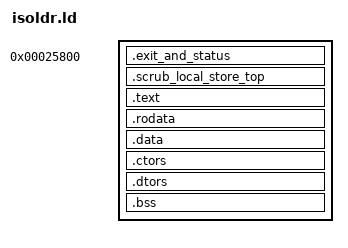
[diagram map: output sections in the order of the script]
ENTRY(_start)

SECTIONS
{
  . = 0x25800;

  .exit_and_status :
  {
    */isoldr/src/exit_stop.o(.text.exit_stop)
    */isoldr/src/exit_stop.o(.data.exit_status)
  }

  .scrub_local_store_top :
  {
    */isoldr/src/scrub.o(.text.scrub)
  }

  .text ALIGN(0x10) :
  {
    */isoldr/src/crt0.o(.text)
    */isoldr/src/g_loader.o(.text._Z41__static_initialization_and_destruction_0ii)
    */isoldr/src/g_loader.o(.text._GLOBAL__I_g_loader)
    */isoldr/src/main.o(.text.main)
    */isoldr/src/loader.o(.text._ZN6loader13apply_qa_flagEv)
    */isoldr/src/loader.o(.text._ZN6loader14check_revisionEv)
    */isoldr/src/loader.o(.text._ZN6loader13select_keysetEt)
    *(.text._ZN9encryptorD0Ev)
    *(.text._ZN9encryptorD1Ev)
    *(.text._ZN9encryptorD2Ev)
    */isoldr/src/encryptor_aes256_cbc.o(.text._ZN20aes256_cbc_encryptorD0Ev)
    *(.text._ZN20aes256_cbc_encryptorD1Ev)
    */isoldr/src/encryptor_aes256_cbc.o(.text._Z41__static_initialization_and_destruction_0ii)
    */isoldr/src/encryptor_aes256_cbc.o(.text._GLOBAL__D_g_aes256_cbc_encryptor)
    */isoldr/src/encryptor_aes256_cbc.o(.text._GLOBAL__I_g_aes256_cbc_encryptor)
    */isoldr/src/loader.o(.text._ZN6loader11export_keysEP7spu_regS1_S1_)
    */isoldr/src/loader.o(.text._ZN6loader12read_requestEv)
    */isoldr/src/loader.o(.text._ZN6loader10takes_keysEv)
    */isoldr/src/loader.o(.text._ZN6loader10load_stateEv)
    */isoldr/src/loader.o(.text._ZN6loaderC1Ev)
    */isoldr/src/loader.o(.text._ZN6loaderC2Ev)
    */isoldr/src/loader.o(.text._ZN6loader13check_qa_flagEv)
    */isoldr/src/loader.o(.text._ZN6loader11open_paramsEv)
    */isoldr/src/loader.o(.text._ZN6loader12export_stateEP7spu_regS1_S1_S1_S1_S1_S1_S1_S1_S1_S1_S1_S1_S1_S1_S1_)
    *(.text._ZN12local_bufferD1Ev)
    *(.text._ZN17tagged_dma_bufferD1Ev)
    */isoldr/src/loader.o(.text._ZN6loader11load_headerEv)
    */isoldr/src/loader.o(.text._ZN6loader17check_revoke_listEv)
    */isoldr/src/loader.o(.text._ZN6loader13load_segmentsEPPFvvE)
    */isoldr/src/loader.o(.text._ZN6loader4loadEPPFvvE)
    */isoldr/src/loader.o(.text._ZN6loader3runEPyS0_S0_S0_P7spu_regS2_S2_S2_S2_S2_S2_S2_S2_S2_S2_S2_S2_S2_S2_S2_PPFvvES0_)
    *(.text._ZN6cipher6vslot6EPKv)
    *(.text._ZN6cipher6vslot7EPv)
    */isoldr/src/hmac_digest.o(.text._ZN11hmac_digestC1Ev)
    */isoldr/src/hmac_digest.o(.text._ZN11hmac_digestC2Ev)
    */lv2ldr/src/hash_reader.o(.text._Z12bytes_differPKhS0_i)
    */isoldr/src/qa_flag.o(.text._ZN14qa_flag_reader4initEv)
    *(.text._ZN6cipherD0Ev)
    *(.text._ZN6cipherD1Ev)
    *(.text._ZN6cipherD2Ev)
    */isoldr/src/cipher_aes256_cbc.o(.text._ZN17aes256_cbc_cipherD0Ev)
    *(.text._ZN17aes256_cbc_cipherD1Ev)
    *(.text._ZN8verifierD0Ev)
    *(.text._ZN8verifierD1Ev)
    *(.text._ZN8verifierD2Ev)
    */isoldr/src/verifier_ecdsa.o(.text._ZN14ecdsa_verifierD0Ev)
    *(.text._ZN14ecdsa_verifierD1Ev)
    */isoldr/src/qa_flag.o(.text._ZN14qa_flag_reader5checkEjPKhPhS1_S1_)
    *(.text._ZN17aes256_cbc_cipherC1Ev)
    */isoldr/src/cipher_aes256_cbc.o(.text._Z41__static_initialization_and_destruction_0ii)
    */isoldr/src/cipher_aes256_cbc.o(.text._GLOBAL__D_g_aes256_cbc)
    */isoldr/src/cipher_aes256_cbc.o(.text._GLOBAL__I_g_aes256_cbc)
    */isoldr/src/cipher_aes256_cbc.o(.text._ZN17aes256_cbc_cipher7decryptEPKviPv)
    */isoldr/src/cipher_aes256_cbc.o(.text._ZN17aes256_cbc_cipher7set_keyEPKhS1_)
    *(.text._ZN20aes256_cbc_encryptorC1Ev)
    */isoldr/src/encryptor_aes256_cbc.o(.text._ZN20aes256_cbc_encryptor7set_keyEPKhPK9cipher_iv)
    */isoldr/src/encryptor_aes256_cbc.o(.text._ZN20aes256_cbc_encryptor7encryptEPKviPv)
    */lv2ldr/src/auth_checks.o(.text._ZeqRK10auth_flagsS1_)
    */lv2ldr/src/auth_checks.o(.text._ZanRK10auth_flagsS1_)
    */lv2ldr/src/auth_checks.o(.text._ZN13authenticator19check_auth_id_classEyy)
    */lv2ldr/src/auth_checks.o(.text._ZN13authenticator18has_required_flagsEv)
    */lv2ldr/src/auth_checks.o(.text._ZN13authenticator12check_issuerEyy)
    */isoldr/src/verifier_ecdsa.o(.text._ZN14ecdsa_verifier6verifyEPKhiS1_)
    */isoldr/src/verifier_ecdsa.o(.text._ZN14ecdsa_verifierC1EPKhj)
    */isoldr/src/verifier_ecdsa.o(.text._ZN14ecdsa_verifierC2EPKhj)
    */lv2ldr/src/auth_checks.o(.text._ZN13authenticator9get_stateEPy)
    */lv2ldr/src/auth_checks.o(.text._ZN13authenticator12get_app_infoEP13auth_app_info)
    */isoldr/src/auth_state_data.o(.text._ZN13authenticator14get_state_dataEPhj)
    */lv1ldr/src/loader_params.o(.text._ZN11param_block4initEv)
    */lv1ldr/src/loader_params.o(.text._ZN11param_block4openEPKhjS1_S1_S1_S1_PjPhS3_)
    */isoldr/src/auth_state_data.o(.text._ZN13authenticator8flag_1b9Ev)
    */lv2ldr/src/auth_checks.o(.text._ZN10auth_state3getEPy)
    */isoldr/src/auth_state_data.o(.text._ZN10auth_state8get_dataEPhj)
    */lv1ldr/src/auth_buffers.o(.text._ZN10auth_state4loadEPK10auth_entryy)
    */lv1ldr/src/auth_buffers.o(.text._ZN10auth_stateC1Ev)
    */lv1ldr/src/auth_buffers.o(.text._ZN10auth_stateC2Ev)
    */lv2ldr/src/revoke_list.o(.text._ZN11revoke_list4initEv)
    */lv2ldr/src/revoke_list.o(.text._ZN11revoke_list12check_headerEPK18revoke_list_header)
    */lv2ldr/src/revoke_list.o(.text._ZN11revoke_list13check_versionEy)
    */isoldr/src/cipher_aes128_ctr.o(.text._ZN17aes128_ctr_cipherD0Ev)
    */isoldr/src/cipher_aes128_ctr.o(.text._ZN17aes128_ctr_cipherD1Ev)
    */lv2ldr/src/revoke_list.o(.text._ZN11revoke_list15check_encryptedEPK12auth_section)
    */lv2ldr/src/revoke_list.o(.text._ZN11revoke_list11check_plainEPK12auth_section)
    */lv2ldr/src/revoke_list.o(.text._ZN11revoke_list5parseEv)
    */lv2ldr/src/revoke_list.o(.text._ZN11revoke_list4openEPKhS1_S1_PKj)
    */lv2ldr/src/revoke_list.o(.text._ZN11revoke_list4loadEPKv)
    */lv1ldr/src/authenticator.o(.text._ZN9elf_imageC1Ev)
    */lv1ldr/src/authenticator.o(.text._ZN9elf_image4loadEPKv)
    */lv1ldr/src/authenticator.o(.text._ZN13authenticator10set_offsetEy)
    */lv1ldr/src/authenticator.o(.text._ZN13authenticator14check_app_infoEPK13auth_app_infoj)
    */lv1ldr/src/authenticator.o(.text._ZN13authenticator9check_appEP9sce_imagej)
    */lv1ldr/src/authenticator.o(.text._ZN13authenticator11load_headerEjPKhS1_S1_PKjPP10dma_bufferj)
    */lv1ldr/src/authenticator.o(.text._ZN13authenticator11clear_partsEv)
    */lv1ldr/src/authenticator.o(.text._ZN13authenticatorC1Ev)
    */lv1ldr/src/authenticator.o(.text._ZN13authenticatorC2Ev)
    */isoldr/src/elf_reader32.o(.text._ZN13authenticator19read_program_headerEjP10Elf32_Phdr)
    */isoldr/src/elf_reader32.o(.text._ZN13authenticator15read_elf_headerEP10Elf32_Ehdr)
    */lv1ldr/src/authenticator.o(.text._ZN10auth_block3getEPy)
    */lv1ldr/src/auth_buffers.o(.text._ZN10auth_block4loadEPK10auth_entryy)
    */lv1ldr/src/auth_buffers.o(.text._ZN10auth_blockC1Ev)
    */lv1ldr/src/auth_buffers.o(.text._ZN10auth_blockC2Ev)
    */isoldr/src/hmac_digest.o(.text._Z41__static_initialization_and_destruction_0ii)
    */isoldr/src/hmac_digest.o(.text._GLOBAL__I_g_hmac)
    */isoldr/src/hmac_digest.o(.text._GLOBAL__D_g_hmac)
    */isoldr/src/hmac_digest.o(.text._ZN11hmac_digest6updateEPKhi)
    */isoldr/src/hmac_digest.o(.text._ZN11hmac_digest5finalEPh)
    */isoldr/src/hmac_digest.o(.text._ZN11hmac_digest4initEPKhj)
    */isoldr/src/hmac_digest.o(.text._ZN11hmac_digest6digestEPKhiPhS1_j)
    */lv2ldr/src/revoke_check.o(.text._ZN11revoke_list10is_revokedEjyy)
    */lv1ldr/src/auth_buffers.o(.text._ZN11header_data5clearEv)
    */lv1ldr/src/auth_buffers.o(.text._ZN9auth_tailC1Ev)
    */lv1ldr/src/auth_buffers.o(.text._ZN9auth_tailC2Ev)
    */isoldr/src/auth_segments.o(.text._ZN13authenticator12load_segmentEjjyPP10dma_bufferiS2_i)
    */lv1ldr/src/auth_transfer.o(.text._ZN13authenticator15transfer_storedEv)
    */isoldr/src/cipher_aes128_ctr.o(.text._ZN17aes128_ctr_cipherC1Ev)
    */isoldr/src/cipher_aes128_ctr.o(.text._Z41__static_initialization_and_destruction_0ii)
    */isoldr/src/cipher_aes128_ctr.o(.text._GLOBAL__D_g_aes128_ctr)
    */isoldr/src/cipher_aes128_ctr.o(.text._GLOBAL__I_g_aes128_ctr)
    */isoldr/src/cipher_aes128_ctr.o(.text._ZN17aes128_ctr_cipher7decryptEPKviPv)
    */isoldr/src/cipher_aes128_ctr.o(.text._ZN17aes128_ctr_cipher7set_keyEPKhS1_)
    */lv1ldr/src/auth_buffers.o(.text._ZN13authenticator7prependEPK10dma_bufferj)
    */lv1ldr/src/auth_buffers.o(.text._ZN13authenticator17check_part_digestEPK12auth_section)
    */lv1ldr/src/auth_buffers.o(.text._ZN9auth_sink6appendEPKU8__vectorhS2_)
    */lv1ldr/src/auth_buffers.o(.text._ZN13authenticator10read_partsEv)
    */lv1ldr/src/auth_buffers.o(.text._ZN13authenticator9save_tailEPK10dma_buffer)
    */lv1ldr/src/auth_buffers.o(.text._ZN13authenticator12restore_tailEPK10dma_buffer)
    */lv1ldr/src/auth_buffers.o(.text._ZN13authenticator12find_sectionEjjP12auth_section)
    */isoldr/src/elf_reader32.o(.text._ZN9elf_image10get_headerEP10Elf32_Ehdr)
    */isoldr/src/elf_reader32.o(.text._ZN9elf_image18get_program_headerEjP10Elf32_Phdr)
    */lv2ldr/src/revoke_scan.o(.text._ZN11revoke_list10scan_pairsEyy)
    */lv2ldr/src/revoke_scan.o(.text._ZN11revoke_list11scan_pairs2Eyy)
    */lv2ldr/src/revoke_scan.o(.text._ZN11revoke_list10scan_rulesEjyy)
    */isoldr/src/dma_queue.o(.text._ZN9dma_queue12enqueue_readEP10dma_buffer)
    */isoldr/src/dma_queue.o(.text._ZN9dma_queue7dequeueEPP10dma_bufferP9list_nodeMS0_FbvE)
    */isoldr/src/dma_queue.o(.text._ZN9dma_queue12dequeue_readEPP10dma_buffer)
    */isoldr/src/dma_queue.o(.text._ZN9dma_queue5drainEP9list_nodeM10dma_bufferFbvE)
    */isoldr/src/dma_queue.o(.text._ZN9dma_queue5closeEv)
    */isoldr/src/dma_queue.o(.text._ZN9dma_queueC1Ev)
    */isoldr/src/dma_queue.o(.text._ZN9dma_queueC2Ev)
    */isoldr/src/dma_queue.o(.text._ZN9dma_queue11add_writtenEP10dma_buffer)
    */isoldr/src/dma_queue.o(.text._ZN9dma_queue13enqueue_writeEP10dma_buffer)
    */isoldr/src/dma_queue.o(.text._ZN9dma_queue13dequeue_writeEPP10dma_buffer)
    */isoldr/src/dma_queue.o(.text._ZN9dma_queue4openEyjyj)
    */isoldr/src/dma_buffer.o(.text._ZN10dma_buffer10set_bufferEjj)
    *(.text._ZN10dma_bufferD0Ev)
    *(.text._ZN10dma_bufferD1Ev)
    *(.text._ZN10dma_bufferD2Ev)
    */isoldr/src/dma_buffer.o(.text._ZN10dma_bufferC1Ev)
    */isoldr/src/dma_buffer.o(.text._ZN10dma_bufferC2Ev)
    */isoldr/src/dma_buffer.o(.text._ZN17tagged_dma_buffer9max_chunkEj)
    */isoldr/src/dma_buffer_io.o(.text._ZN17tagged_dma_bufferD0Ev)
    *(.text._ZN7dma_mfcC1Ev)
    */isoldr/src/dma_buffer.o(.text._Z41__static_initialization_and_destruction_0ii)
    */isoldr/src/dma_buffer.o(.text._GLOBAL__I__ZN10dma_bufferC2Ev)
    */isoldr/src/dma_buffer.o(.text._ZN17tagged_dma_buffer8transferEyyjj)
    */isoldr/src/dma_buffer.o(.text._ZN17tagged_dma_buffer8put_doneEv)
    */isoldr/src/dma_buffer.o(.text._ZN17tagged_dma_buffer8get_doneEv)
    */isoldr/src/dma_buffer.o(.text._ZN17tagged_dma_bufferC1Ej)
    */isoldr/src/dma_buffer.o(.text._ZN17tagged_dma_bufferC2Ej)
    */isoldr/src/dma_buffer_io.o(.text._ZN17tagged_dma_buffer3putEyjPj)
    */isoldr/src/dma_buffer_io.o(.text._ZN17tagged_dma_buffer3getEyjPj)
    */isoldr/src/local_buffer.o(.text._ZN12local_buffer3getEyjPj)
    */isoldr/src/local_buffer.o(.text._ZN12local_buffer8get_doneEv)
    */isoldr/src/local_buffer.o(.text._ZN12local_buffer8put_doneEv)
    */isoldr/src/local_buffer.o(.text._ZN12local_bufferD0Ev)
    */isoldr/src/local_buffer.o(.text._ZN12local_bufferC1Ev)
    */isoldr/src/local_buffer.o(.text._ZN12local_bufferC2Ev)
    */isoldr/src/local_buffer.o(.text._ZN12local_buffer3putEyjPj)
    */lv0ldr/crypto/aes_set_encrypt_key.o(.text)
    */lv0ldr/crypto/aes_encrypt_block.o(.text)
    */lv0ldr/crypto/aes_cbc_encrypt.o(.text)
    */lv0ldr/crypto/aes_modes.o(.text)
    */isoldr/crypto/aes_cmac.o(.text)
    */lv0ldr/crypto/sha1_digest.o(.text)
    */lv0ldr/crypto/hmac_sha1.o(.text)
    */isoldr/crypto/hmac_sha1_once.o(.text)
    */lv0ldr/crypto/aes_set_decrypt_key.o(.text)
    */lv0ldr/crypto/aes_blocks.o(.text)
    */lv0ldr/crypto/sha1.o(.text)
    */lv0ldr/crypto/sha1_transform.o(.text)
    */isoldr/crypto/ecdsa.o(.text)
    */lv0ldr/crypto/ec.o(.text)
    */lv0ldr/crypto/ec_mul2.o(.text)
    */lv0ldr/crypto/bn_core.o(.text)
    */lv0ldr/crypto/bn_in_range.o(.text)
    */lv0ldr/crypto/ec_curve_valid.o(.text)
    */lv0ldr/crypto/ecdsa_id.o(.text)
    */lv0ldr/crypto/ec_curves.o(.text)
    */lv0ldr/crypto/bn_from_bytes_not.o(.text)
    */isoldr/src/mfc.o(.text._ZN8mfc_baseC1Ev)
    */isoldr/src/mfc.o(.text._ZN8mfc_baseC2Ev)
    */isoldr/src/mfc.o(.text._Z13mbox_in_countv)
    */isoldr/src/mfc.o(.text._Z9mfc_issuejyjjjj)
    */isoldr/src/mfc.o(.text._Z12mfc_tag_donej)
    */isoldr/src/mfc.o(.text._Z19mbox_out_intr_writej)
    */isoldr/src/mfc.o(.text._Z14mbox_out_writej)
    */isoldr/src/mfc.o(.text._Z12mbox_in_readPj)
    */isoldr/src/mbox_drain.o(.text._Z13mbox_in_drainv)
    */lv0ldr/src/util/cxx_runtime.o(.text._ZdlPv)
    */lv0ldr/src/util/cxx_runtime.o(.text.__cxa_pure_virtual)
    */isoldr/src/ch64.o(.text._Z12ch64_requestv)
    */lv2ldr/src/ch72.o(.text._Z8ch72_getiPji)
    */lv2ldr/src/ch72.o(.text._Z14ch72_get_replyPh)
    */lv2ldr/src/ch72.o(.text._Z16ch72_get_versionPy)
    */lv2ldr/src/ch72.o(.text._Z20ch72_compare_versiony)
    */lv2ldr/src/ch72.o(.text._Z11ch72_unwrapPU8__vectorhPKS_iPKhiS2_)
    */lv2ldr/src/ch72.o(.text._Z14ch72_unwrap_ivPU8__vectorhPKS_i)
    */lv2ldr/src/ch72.o(.text._Z15ch72_unwrap_keyPU8__vectorhPKS_i)
    */lv1ldr/src/auth_header.o(.text._ZN9sce_image12get_sectionsEv)
    */lv1ldr/src/auth_header.o(.text._ZN9sce_image17get_section_countEPj)
    */lv1ldr/src/auth_header.o(.text._ZN9sce_image13get_key_countEPj)
    */lv1ldr/src/auth_header.o(.text._ZN9sce_image14get_ext_headerEPjS0_)
    */lv1ldr/src/auth_check.o(.text._Z16check_sce_headerPKU8__vectorhPKvtj)
    */lv1ldr/src/auth_check.o(.text._Z17check_meta_headerPKU8__vectorhPK9auth_metaj)
    */lv1ldr/src/auth_check.o(.text._Z14check_sectionsP9sce_image)
    */lv1ldr/src/auth_check.o(.text._Z18check_control_infoPK12auth_controly)
    */lv1ldr/src/auth_check.o(.text._Z16check_ext_headerP9sce_image)
    */lv1ldr/src/auth_check.o(.text._ZN9sce_image12get_app_infoEPj)
    */lv0ldr/src/boot/exit.o(.text.exit)
    */lv0ldr/src/util/memcmp.o(.text.memcmp)
    */isoldr/src/memset.o(.text.memset)
    */isoldr/src/memcpy.o(.text.memcpy)
    *(.text .text.* .gnu.linkonce.t.*)
  }

  .rodata :
  {
    */isoldr/src/loader.o(.rodata.cst16)
    */isoldr/src/loader_data.o(.rodata.g_list_curve)
    *(.rodata._ZTV20aes256_cbc_encryptor)
    *(.rodata._ZTV9encryptor)
    */isoldr/src/loader_data.o(.rodata.g_key_seed)
    */isoldr/src/loader_data.o(.rodata.g_qa_debug_bit)
    */isoldr/src/loader_data.o(.rodata.g_params_seed)
    */isoldr/src/loader_data.o(.rodata.g_list_pub)
    *(.rodata._ZTV17aes256_cbc_cipher)
    *(.rodata._ZTV6cipher)
    *(.rodata._ZTV14ecdsa_verifier)
    *(.rodata._ZTV8verifier)
    */isoldr/src/qa_flag_data.o(.rodata.qa_flag_pub)
    */lv2ldr/src/auth_checks.o(.rodata.cst16)
    */isoldr/src/auth_data.o(.rodata.g_required_flags)
    */isoldr/src/auth_data.o(.rodata.params_seed)
    */lv1ldr/src/auth_buffers.o(.rodata.cst16)
    */lv2ldr/src/revoke_list.o(.rodata.cst16)
    *(.rodata._ZTV17aes128_ctr_cipher)
    */lv1ldr/src/authenticator.o(.rodata.cst16)
    *(.rodata._ZTV10dma_buffer)
    *(.rodata._ZTV17tagged_dma_buffer)
    *(.rodata._ZTV12local_buffer)
    */isoldr/src/*.o(.rodata.cst16)
    */crypto/*.o(.rodata .rodata.*)
    */isoldr/src/auth_data.o(.rodata.ch72_key_data)
    */isoldr/src/auth_data.o(.rodata.ch72_iv_data)
    */isoldr/src/auth_data.o(.rodata.ch72_key_iv)
    */isoldr/src/auth_data.o(.rodata.ch72_iv_iv)
    */isoldr/src/auth_data.o(.rodata.key_slots)
    */isoldr/src/auth_data.o(.rodata.digest_slots)
    */isoldr/src/auth_data.o(.rodata.sig_sizes)
    */lv1ldr/src/auth_check.o(.rodata.cst16)
    */isoldr/src/auth_data.o(.rodata.control_digest)
    */lv0ldr/src/util/shuffle_table.o(.rodata .rodata.*)
    *(.rodata .rodata.* .gnu.linkonce.r.*)
  }

  . = ALIGN(0x80) + (. & (0x80 - 1));
  .data :
  {
    */isoldr/src/loader_data.o(.data.g_list_key)
    */isoldr/src/loader_data.o(.data.g_list_iv)
    */isoldr/src/loader_data.o(.data.g_keysets)
    */isoldr/src/loader_data.o(.data.g_debug_keysets)
    */isoldr/src/loader_data.o(.data.g_keyset_100)
    */isoldr/src/qa_flag_data.o(.data.qa_flag_hmac_key)
    */isoldr/src/qa_flag_data.o(.data.qa_flag_key)
    */isoldr/src/qa_flag_data.o(.data.qa_flag_iv)
    */isoldr/src/qa_flag_data.o(.data.qa_flag_curve)
    *(.data .data.* .gnu.linkonce.d.*)
  }
  .ctors : { KEEP(*(.ctors)) __CTOR_END__ = .; }
  .dtors : { KEEP(*(.dtors)) }
  .bss :
  {
    */isoldr/src/g_loader.o(.bss.g_loader)
    */isoldr/src/loader_data.o(.bss.g_ls_key)
    */isoldr/src/loader_data.o(.bss.g_ls_iv)
    */isoldr/src/encryptor_aes256_cbc.o(.bss.g_aes256_cbc_encryptor)
    */isoldr/src/loader_data.o(.bss.g_qa_flag)
    */isoldr/src/loader_data.o(.bss.g_qa_request)
    */isoldr/src/loader_data.o(.bss.g_revoke_list)
    */isoldr/src/loader_data.o(.bss.g_auth_area)
    */isoldr/src/cipher_aes256_cbc.o(.bss.g_aes256_cbc)
    */isoldr/src/verifier_ecdsa.o(.bss.verify_hash)
    */isoldr/src/auth_data.o(.bss.g_revoke_buf)
    */isoldr/src/auth_data.o(.bss.g_revoke_digest)
    */lv1ldr/src/auth_buffers.o(.bss.g_part_area)
    */lv1ldr/src/auth_buffers.o(.bss.g_part_digest)
    */lv1ldr/src/auth_buffers.o(.bss.g_header)
    */isoldr/src/hmac_digest.o(.bss.g_hmac)
    */isoldr/src/cipher_aes128_ctr.o(.bss.g_aes128_ctr)
    */isoldr/src/dma_buffer.o(.bss.g_dma_mfc)
    *(.bss .bss.* .gnu.linkonce.b.*)
    *(COMMON)
  }

  /DISCARD/ : { *(.comment) *(.note*) *(.eh_frame) }
}
